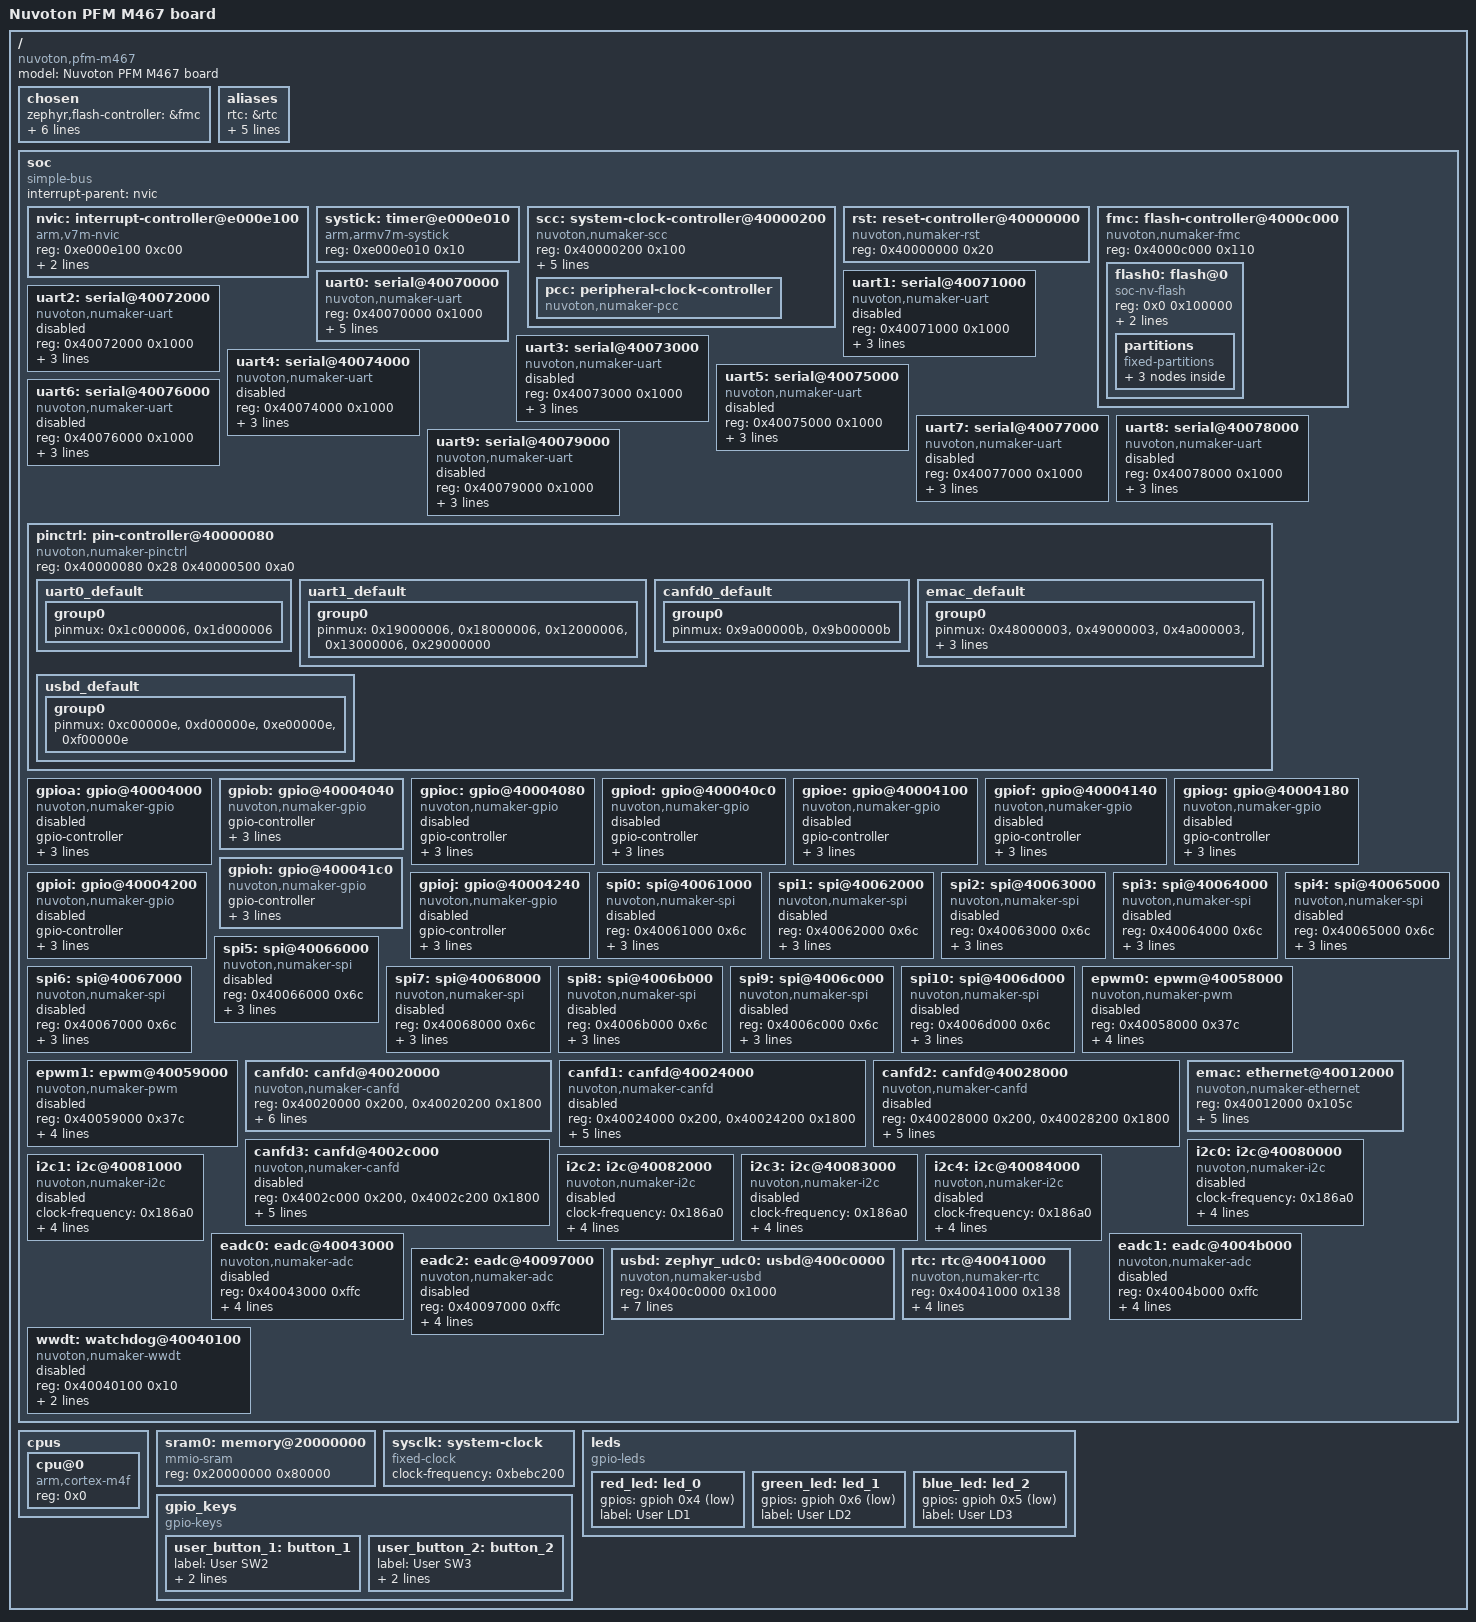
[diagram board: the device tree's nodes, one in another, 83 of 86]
/dts-v1/;

/* node '/' defined in zephyr/dts/common/skeleton.dtsi:9 */
/ {
	#address-cells = < 0x1 >;         /* in zephyr/dts/common/skeleton.dtsi:10 */
	#size-cells = < 0x1 >;            /* in zephyr/dts/common/skeleton.dtsi:11 */
	model = "Nuvoton PFM M467 board"; /* in zephyr/boards/nuvoton/numaker_pfm_m467/numaker_pfm_m467.dts:14 */
	compatible = "nuvoton,pfm-m467",
	             "nuvoton,m467";      /* in zephyr/boards/nuvoton/numaker_pfm_m467/numaker_pfm_m467.dts:15 */

	/* node '/chosen' defined in zephyr/dts/common/skeleton.dtsi:13 */
	chosen {
		zephyr,flash-controller = &fmc;           /* in zephyr/dts/arm/nuvoton/m46x.dtsi:18 */
		zephyr,console = &uart0;                  /* in zephyr/boards/nuvoton/numaker_pfm_m467/numaker_pfm_m467.dts:26 */
		zephyr,shell-uart = &uart0;               /* in zephyr/boards/nuvoton/numaker_pfm_m467/numaker_pfm_m467.dts:27 */
		zephyr,sram = &sram0;                     /* in zephyr/boards/nuvoton/numaker_pfm_m467/numaker_pfm_m467.dts:28 */
		zephyr,flash = &flash0;                   /* in zephyr/boards/nuvoton/numaker_pfm_m467/numaker_pfm_m467.dts:29 */
		zephyr,code-partition = &slot0_partition; /* in zephyr/boards/nuvoton/numaker_pfm_m467/numaker_pfm_m467.dts:30 */
		zephyr,canbus = &canfd0;                  /* in zephyr/boards/nuvoton/numaker_pfm_m467/numaker_pfm_m467.dts:31 */
	};

	/* node '/aliases' defined in zephyr/dts/common/skeleton.dtsi:15 */
	aliases {
		rtc = &rtc;           /* in zephyr/dts/arm/nuvoton/m46x.dtsi:22 */
		led0 = &green_led;    /* in zephyr/boards/nuvoton/numaker_pfm_m467/numaker_pfm_m467.dts:18 */
		led1 = &blue_led;     /* in zephyr/boards/nuvoton/numaker_pfm_m467/numaker_pfm_m467.dts:19 */
		led2 = &red_led;      /* in zephyr/boards/nuvoton/numaker_pfm_m467/numaker_pfm_m467.dts:20 */
		sw0 = &user_button_1; /* in zephyr/boards/nuvoton/numaker_pfm_m467/numaker_pfm_m467.dts:21 */
		sw1 = &user_button_2; /* in zephyr/boards/nuvoton/numaker_pfm_m467/numaker_pfm_m467.dts:22 */
	};

	/* node '/soc' defined in zephyr/dts/arm/armv7-m.dtsi:6 */
	soc {
		#address-cells = < 0x1 >;     /* in zephyr/dts/arm/armv7-m.dtsi:7 */
		#size-cells = < 0x1 >;        /* in zephyr/dts/arm/armv7-m.dtsi:8 */
		compatible = "simple-bus";    /* in zephyr/dts/arm/armv7-m.dtsi:9 */
		interrupt-parent = < &nvic >; /* in zephyr/dts/arm/armv7-m.dtsi:10 */
		ranges;                       /* in zephyr/dts/arm/armv7-m.dtsi:11 */

		/* node '/soc/interrupt-controller@e000e100' defined in zephyr/dts/arm/armv7-m.dtsi:13 */
		nvic: interrupt-controller@e000e100 {
			#address-cells = < 0x1 >;            /* in zephyr/dts/arm/armv7-m.dtsi:14 */
			compatible = "arm,v7m-nvic";         /* in zephyr/dts/arm/armv7-m.dtsi:15 */
			reg = < 0xe000e100 0xc00 >;          /* in zephyr/dts/arm/armv7-m.dtsi:16 */
			interrupt-controller;                /* in zephyr/dts/arm/armv7-m.dtsi:17 */
			#interrupt-cells = < 0x2 >;          /* in zephyr/dts/arm/armv7-m.dtsi:18 */
			arm,num-irq-priority-bits = < 0x4 >; /* in zephyr/dts/arm/nuvoton/m46x.dtsi:638 */
			phandle = < 0x1 >;                   /* in zephyr/dts/arm/armv7-m.dtsi:10 */
		};

		/* node '/soc/timer@e000e010' defined in zephyr/dts/arm/armv7-m.dtsi:21 */
		systick: timer@e000e010 {
			compatible = "arm,armv7m-systick"; /* in zephyr/dts/arm/armv7-m.dtsi:22 */
			reg = < 0xe000e010 0x10 >;         /* in zephyr/dts/arm/armv7-m.dtsi:23 */
		};

		/* node '/soc/system-clock-controller@40000200' defined in zephyr/dts/arm/nuvoton/m46x.dtsi:48 */
		scc: system-clock-controller@40000200 {
			compatible = "nuvoton,numaker-scc"; /* in zephyr/dts/arm/nuvoton/m46x.dtsi:49 */
			reg = < 0x40000200 0x100 >;         /* in zephyr/dts/arm/nuvoton/m46x.dtsi:50 */
			#clock-cells = < 0x0 >;             /* in zephyr/dts/arm/nuvoton/m46x.dtsi:51 */
			lxt = "enable";                     /* in zephyr/dts/arm/nuvoton/m46x.dtsi:53 */
			hirc48m = "enable";                 /* in zephyr/dts/arm/nuvoton/m46x.dtsi:54 */
			clk-pclkdiv = < 0x11 >;             /* in zephyr/dts/arm/nuvoton/m46x.dtsi:55 */
			powerdown-mode = < 0x6 >;           /* in zephyr/dts/arm/nuvoton/m46x.dtsi:58 */
			core-clock = < 0xb71b000 >;         /* in zephyr/boards/nuvoton/numaker_pfm_m467/numaker_pfm_m467.dts:71 */

			/* node '/soc/system-clock-controller@40000200/peripheral-clock-controller' defined in zephyr/dts/arm/nuvoton/m46x.dtsi:60 */
			pcc: peripheral-clock-controller {
				compatible = "nuvoton,numaker-pcc"; /* in zephyr/dts/arm/nuvoton/m46x.dtsi:61 */
				#clock-cells = < 0x3 >;             /* in zephyr/dts/arm/nuvoton/m46x.dtsi:62 */
				phandle = < 0x3 >;                  /* in zephyr/dts/arm/nuvoton/m46x.dtsi:92 */
			};
		};

		/* node '/soc/reset-controller@40000000' defined in zephyr/dts/arm/nuvoton/m46x.dtsi:66 */
		rst: reset-controller@40000000 {
			compatible = "nuvoton,numaker-rst"; /* in zephyr/dts/arm/nuvoton/m46x.dtsi:67 */
			reg = < 0x40000000 0x20 >;          /* in zephyr/dts/arm/nuvoton/m46x.dtsi:68 */
			#reset-cells = < 0x1 >;             /* in zephyr/dts/arm/nuvoton/m46x.dtsi:69 */
			status = "okay";                    /* in zephyr/dts/arm/nuvoton/m46x.dtsi:70 */
			phandle = < 0x2 >;                  /* in zephyr/dts/arm/nuvoton/m46x.dtsi:91 */
		};

		/* node '/soc/flash-controller@4000c000' defined in zephyr/dts/arm/nuvoton/m46x.dtsi:73 */
		fmc: flash-controller@4000c000 {
			compatible = "nuvoton,numaker-fmc"; /* in zephyr/dts/arm/nuvoton/m46x.dtsi:74 */
			reg = < 0x4000c000 0x110 >;         /* in zephyr/dts/arm/nuvoton/m46x.dtsi:75 */
			#address-cells = < 0x1 >;           /* in zephyr/dts/arm/nuvoton/m46x.dtsi:76 */
			#size-cells = < 0x1 >;              /* in zephyr/dts/arm/nuvoton/m46x.dtsi:77 */

			/* node '/soc/flash-controller@4000c000/flash@0' defined in zephyr/dts/arm/nuvoton/m46x.dtsi:79 */
			flash0: flash@0 {
				compatible = "soc-nv-flash";   /* in zephyr/dts/arm/nuvoton/m46x.dtsi:80 */
				reg = < 0x0 0x100000 >;        /* in zephyr/dts/arm/nuvoton/m46x.dtsi:81 */
				erase-block-size = < 0x1000 >; /* in zephyr/dts/arm/nuvoton/m46x.dtsi:82 */
				write-block-size = < 0x4 >;    /* in zephyr/dts/arm/nuvoton/m46x.dtsi:83 */

				/* node '/soc/flash-controller@4000c000/flash@0/partitions' defined in zephyr/boards/nuvoton/numaker_pfm_m467/numaker_pfm_m467.dts:83 */
				partitions {
					compatible = "fixed-partitions"; /* in zephyr/boards/nuvoton/numaker_pfm_m467/numaker_pfm_m467.dts:84 */
					#address-cells = < 0x1 >;        /* in zephyr/boards/nuvoton/numaker_pfm_m467/numaker_pfm_m467.dts:85 */
					#size-cells = < 0x1 >;           /* in zephyr/boards/nuvoton/numaker_pfm_m467/numaker_pfm_m467.dts:86 */

					/* node '/soc/flash-controller@4000c000/flash@0/partitions/partition@0' defined in zephyr/boards/nuvoton/numaker_pfm_m467/numaker_pfm_m467.dts:88 */
					slot0_partition: partition@0 {
						label = "image-0";     /* in zephyr/boards/nuvoton/numaker_pfm_m467/numaker_pfm_m467.dts:89 */
						reg = < 0x0 0x80000 >; /* in zephyr/boards/nuvoton/numaker_pfm_m467/numaker_pfm_m467.dts:90 */
					};

					/* node '/soc/flash-controller@4000c000/flash@0/partitions/partition@80000' defined in zephyr/boards/nuvoton/numaker_pfm_m467/numaker_pfm_m467.dts:93 */
					slot1_partition: partition@80000 {
						label = "image-1";         /* in zephyr/boards/nuvoton/numaker_pfm_m467/numaker_pfm_m467.dts:94 */
						reg = < 0x80000 0x7e000 >; /* in zephyr/boards/nuvoton/numaker_pfm_m467/numaker_pfm_m467.dts:95 */
					};

					/* node '/soc/flash-controller@4000c000/flash@0/partitions/partition@fe000' defined in zephyr/boards/nuvoton/numaker_pfm_m467/numaker_pfm_m467.dts:98 */
					storage_partition: partition@fe000 {
						label = "storage";        /* in zephyr/boards/nuvoton/numaker_pfm_m467/numaker_pfm_m467.dts:99 */
						reg = < 0xfe000 0x2000 >; /* in zephyr/boards/nuvoton/numaker_pfm_m467/numaker_pfm_m467.dts:100 */
					};
				};
			};
		};

		/* node '/soc/serial@40070000' defined in zephyr/dts/arm/nuvoton/m46x.dtsi:87 */
		uart0: serial@40070000 {
			compatible = "nuvoton,numaker-uart";        /* in zephyr/dts/arm/nuvoton/m46x.dtsi:88 */
			reg = < 0x40070000 0x1000 >;                /* in zephyr/dts/arm/nuvoton/m46x.dtsi:89 */
			interrupts = < 0x24 0x0 >;                  /* in zephyr/dts/arm/nuvoton/m46x.dtsi:90 */
			resets = < &rst 0x4000010 >;                /* in zephyr/dts/arm/nuvoton/m46x.dtsi:91 */
			clocks = < &pcc 0x24f03d10 0x3000000 0x0 >; /* in zephyr/dts/arm/nuvoton/m46x.dtsi:92 */
			current-speed = < 0x1c200 >;                /* in zephyr/boards/nuvoton/numaker_pfm_m467/numaker_pfm_m467.dts:110 */
			pinctrl-0 = < &uart0_default >;             /* in zephyr/boards/nuvoton/numaker_pfm_m467/numaker_pfm_m467.dts:111 */
			pinctrl-names = "default";                  /* in zephyr/boards/nuvoton/numaker_pfm_m467/numaker_pfm_m467.dts:112 */
			status = "okay";                            /* in zephyr/boards/nuvoton/numaker_pfm_m467/numaker_pfm_m467.dts:113 */
		};

		/* node '/soc/serial@40071000' defined in zephyr/dts/arm/nuvoton/m46x.dtsi:97 */
		uart1: serial@40071000 {
			compatible = "nuvoton,numaker-uart";        /* in zephyr/dts/arm/nuvoton/m46x.dtsi:98 */
			reg = < 0x40071000 0x1000 >;                /* in zephyr/dts/arm/nuvoton/m46x.dtsi:99 */
			interrupts = < 0x25 0x0 >;                  /* in zephyr/dts/arm/nuvoton/m46x.dtsi:100 */
			resets = < &rst 0x4000011 >;                /* in zephyr/dts/arm/nuvoton/m46x.dtsi:101 */
			clocks = < &pcc 0x24f43d91 0xc000000 0x0 >; /* in zephyr/dts/arm/nuvoton/m46x.dtsi:102 */
			status = "disabled";                        /* in zephyr/dts/arm/nuvoton/m46x.dtsi:104 */
		};

		/* node '/soc/serial@40072000' defined in zephyr/dts/arm/nuvoton/m46x.dtsi:107 */
		uart2: serial@40072000 {
			compatible = "nuvoton,numaker-uart";        /* in zephyr/dts/arm/nuvoton/m46x.dtsi:108 */
			reg = < 0x40072000 0x1000 >;                /* in zephyr/dts/arm/nuvoton/m46x.dtsi:109 */
			interrupts = < 0x30 0x0 >;                  /* in zephyr/dts/arm/nuvoton/m46x.dtsi:110 */
			resets = < &rst 0x4000012 >;                /* in zephyr/dts/arm/nuvoton/m46x.dtsi:111 */
			clocks = < &pcc 0x2cf13c12 0x3000000 0x0 >; /* in zephyr/dts/arm/nuvoton/m46x.dtsi:112 */
			status = "disabled";                        /* in zephyr/dts/arm/nuvoton/m46x.dtsi:114 */
		};

		/* node '/soc/serial@40073000' defined in zephyr/dts/arm/nuvoton/m46x.dtsi:117 */
		uart3: serial@40073000 {
			compatible = "nuvoton,numaker-uart";        /* in zephyr/dts/arm/nuvoton/m46x.dtsi:118 */
			reg = < 0x40073000 0x1000 >;                /* in zephyr/dts/arm/nuvoton/m46x.dtsi:119 */
			interrupts = < 0x31 0x0 >;                  /* in zephyr/dts/arm/nuvoton/m46x.dtsi:120 */
			resets = < &rst 0x4000013 >;                /* in zephyr/dts/arm/nuvoton/m46x.dtsi:121 */
			clocks = < &pcc 0x2cf53c93 0xc000000 0x0 >; /* in zephyr/dts/arm/nuvoton/m46x.dtsi:122 */
			status = "disabled";                        /* in zephyr/dts/arm/nuvoton/m46x.dtsi:124 */
		};

		/* node '/soc/serial@40074000' defined in zephyr/dts/arm/nuvoton/m46x.dtsi:127 */
		uart4: serial@40074000 {
			compatible = "nuvoton,numaker-uart";         /* in zephyr/dts/arm/nuvoton/m46x.dtsi:128 */
			reg = < 0x40074000 0x1000 >;                 /* in zephyr/dts/arm/nuvoton/m46x.dtsi:129 */
			interrupts = < 0x4a 0x0 >;                   /* in zephyr/dts/arm/nuvoton/m46x.dtsi:130 */
			resets = < &rst 0x4000014 >;                 /* in zephyr/dts/arm/nuvoton/m46x.dtsi:131 */
			clocks = < &pcc 0x2cf93d14 0x30000000 0x0 >; /* in zephyr/dts/arm/nuvoton/m46x.dtsi:132 */
			status = "disabled";                         /* in zephyr/dts/arm/nuvoton/m46x.dtsi:134 */
		};

		/* node '/soc/serial@40075000' defined in zephyr/dts/arm/nuvoton/m46x.dtsi:137 */
		uart5: serial@40075000 {
			compatible = "nuvoton,numaker-uart";         /* in zephyr/dts/arm/nuvoton/m46x.dtsi:138 */
			reg = < 0x40075000 0x1000 >;                 /* in zephyr/dts/arm/nuvoton/m46x.dtsi:139 */
			interrupts = < 0x4b 0x0 >;                   /* in zephyr/dts/arm/nuvoton/m46x.dtsi:140 */
			resets = < &rst 0x4000015 >;                 /* in zephyr/dts/arm/nuvoton/m46x.dtsi:141 */
			clocks = < &pcc 0x2cfd3d95 0xc0000000 0x0 >; /* in zephyr/dts/arm/nuvoton/m46x.dtsi:142 */
			status = "disabled";                         /* in zephyr/dts/arm/nuvoton/m46x.dtsi:144 */
		};

		/* node '/soc/serial@40076000' defined in zephyr/dts/arm/nuvoton/m46x.dtsi:147 */
		uart6: serial@40076000 {
			compatible = "nuvoton,numaker-uart";       /* in zephyr/dts/arm/nuvoton/m46x.dtsi:148 */
			reg = < 0x40076000 0x1000 >;               /* in zephyr/dts/arm/nuvoton/m46x.dtsi:149 */
			interrupts = < 0x66 0x0 >;                 /* in zephyr/dts/arm/nuvoton/m46x.dtsi:150 */
			resets = < &rst 0x4000016 >;               /* in zephyr/dts/arm/nuvoton/m46x.dtsi:151 */
			clocks = < &pcc 0x2ce93e16 0x300000 0x0 >; /* in zephyr/dts/arm/nuvoton/m46x.dtsi:152 */
			status = "disabled";                       /* in zephyr/dts/arm/nuvoton/m46x.dtsi:154 */
		};

		/* node '/soc/serial@40077000' defined in zephyr/dts/arm/nuvoton/m46x.dtsi:157 */
		uart7: serial@40077000 {
			compatible = "nuvoton,numaker-uart";       /* in zephyr/dts/arm/nuvoton/m46x.dtsi:158 */
			reg = < 0x40077000 0x1000 >;               /* in zephyr/dts/arm/nuvoton/m46x.dtsi:159 */
			interrupts = < 0x67 0x0 >;                 /* in zephyr/dts/arm/nuvoton/m46x.dtsi:160 */
			resets = < &rst 0x4000017 >;               /* in zephyr/dts/arm/nuvoton/m46x.dtsi:161 */
			clocks = < &pcc 0x2ced3e97 0xc00000 0x0 >; /* in zephyr/dts/arm/nuvoton/m46x.dtsi:162 */
			status = "disabled";                       /* in zephyr/dts/arm/nuvoton/m46x.dtsi:164 */
		};

		/* node '/soc/serial@40078000' defined in zephyr/dts/arm/nuvoton/m46x.dtsi:167 */
		uart8: serial@40078000 {
			compatible = "nuvoton,numaker-uart";       /* in zephyr/dts/arm/nuvoton/m46x.dtsi:168 */
			reg = < 0x40078000 0x1000 >;               /* in zephyr/dts/arm/nuvoton/m46x.dtsi:169 */
			interrupts = < 0x63 0x0 >;                 /* in zephyr/dts/arm/nuvoton/m46x.dtsi:170 */
			resets = < &rst 0x18000010 >;              /* in zephyr/dts/arm/nuvoton/m46x.dtsi:171 */
			clocks = < &pcc 0x68e97e10 0x300000 0x0 >; /* in zephyr/dts/arm/nuvoton/m46x.dtsi:172 */
			status = "disabled";                       /* in zephyr/dts/arm/nuvoton/m46x.dtsi:174 */
		};

		/* node '/soc/serial@40079000' defined in zephyr/dts/arm/nuvoton/m46x.dtsi:177 */
		uart9: serial@40079000 {
			compatible = "nuvoton,numaker-uart";       /* in zephyr/dts/arm/nuvoton/m46x.dtsi:178 */
			reg = < 0x40079000 0x1000 >;               /* in zephyr/dts/arm/nuvoton/m46x.dtsi:179 */
			interrupts = < 0x64 0x0 >;                 /* in zephyr/dts/arm/nuvoton/m46x.dtsi:180 */
			resets = < &rst 0x18000011 >;              /* in zephyr/dts/arm/nuvoton/m46x.dtsi:181 */
			clocks = < &pcc 0x68ed7e91 0xc00000 0x0 >; /* in zephyr/dts/arm/nuvoton/m46x.dtsi:182 */
			status = "disabled";                       /* in zephyr/dts/arm/nuvoton/m46x.dtsi:184 */
		};

		/* node '/soc/pin-controller@40000080' defined in zephyr/dts/arm/nuvoton/m46x.dtsi:187 */
		pinctrl: pin-controller@40000080 {
			compatible = "nuvoton,numaker-pinctrl";    /* in zephyr/dts/arm/nuvoton/m46x.dtsi:188 */
			reg = < 0x40000080 0x28 0x40000500 0xa0 >; /* in zephyr/dts/arm/nuvoton/m46x.dtsi:189 */
			reg-names = "mfos",
			            "mfp";                         /* in zephyr/dts/arm/nuvoton/m46x.dtsi:191 */
			status = "okay";                           /* in zephyr/dts/arm/nuvoton/m46x.dtsi:192 */

			/* node '/soc/pin-controller@40000080/uart0_default' defined in zephyr/boards/nuvoton/numaker_pfm_m467/numaker_pfm_m467-pinctrl.dtsi:10 */
			uart0_default: uart0_default {
				phandle = < 0x4 >; /* in zephyr/boards/nuvoton/numaker_pfm_m467/numaker_pfm_m467.dts:111 */

				/* node '/soc/pin-controller@40000080/uart0_default/group0' defined in zephyr/boards/nuvoton/numaker_pfm_m467/numaker_pfm_m467-pinctrl.dtsi:11 */
				group0 {
					pinmux = < 0x1c000006 >,
					         < 0x1d000006 >; /* in zephyr/boards/nuvoton/numaker_pfm_m467/numaker_pfm_m467-pinctrl.dtsi:12 */
				};
			};

			/* node '/soc/pin-controller@40000080/uart1_default' defined in zephyr/boards/nuvoton/numaker_pfm_m467/numaker_pfm_m467-pinctrl.dtsi:18 */
			uart1_default: uart1_default {

				/* node '/soc/pin-controller@40000080/uart1_default/group0' defined in zephyr/boards/nuvoton/numaker_pfm_m467/numaker_pfm_m467-pinctrl.dtsi:19 */
				group0 {
					pinmux = < 0x19000006 >,
					         < 0x18000006 >,
					         < 0x12000006 >,
					         < 0x13000006 >,
					         < 0x29000000 >; /* in zephyr/boards/nuvoton/numaker_pfm_m467/numaker_pfm_m467-pinctrl.dtsi:20 */
				};
			};

			/* node '/soc/pin-controller@40000080/canfd0_default' defined in zephyr/boards/nuvoton/numaker_pfm_m467/numaker_pfm_m467-pinctrl.dtsi:29 */
			canfd0_default: canfd0_default {
				phandle = < 0x5 >; /* in zephyr/boards/nuvoton/numaker_pfm_m467/numaker_pfm_m467.dts:117 */

				/* node '/soc/pin-controller@40000080/canfd0_default/group0' defined in zephyr/boards/nuvoton/numaker_pfm_m467/numaker_pfm_m467-pinctrl.dtsi:30 */
				group0 {
					pinmux = < 0x9a00000b >,
					         < 0x9b00000b >; /* in zephyr/boards/nuvoton/numaker_pfm_m467/numaker_pfm_m467-pinctrl.dtsi:31 */
				};
			};

			/* node '/soc/pin-controller@40000080/emac_default' defined in zephyr/boards/nuvoton/numaker_pfm_m467/numaker_pfm_m467-pinctrl.dtsi:37 */
			emac_default: emac_default {
				phandle = < 0x6 >; /* in zephyr/boards/nuvoton/numaker_pfm_m467/numaker_pfm_m467.dts:123 */

				/* node '/soc/pin-controller@40000080/emac_default/group0' defined in zephyr/boards/nuvoton/numaker_pfm_m467/numaker_pfm_m467-pinctrl.dtsi:38 */
				group0 {
					pinmux = < 0x48000003 >,
					         < 0x49000003 >,
					         < 0x4a000003 >,
					         < 0x4b000003 >,
					         < 0x4c000003 >,
					         < 0x28000003 >,
					         < 0x27000003 >,
					         < 0x26000003 >,
					         < 0x7000003 >,
					         < 0x6000003 >,
					         < 0x16000003 >; /* in zephyr/boards/nuvoton/numaker_pfm_m467/numaker_pfm_m467-pinctrl.dtsi:39 */
				};
			};

			/* node '/soc/pin-controller@40000080/usbd_default' defined in zephyr/boards/nuvoton/numaker_pfm_m467/numaker_pfm_m467-pinctrl.dtsi:54 */
			usbd_default: usbd_default {
				phandle = < 0x7 >; /* in zephyr/boards/nuvoton/numaker_pfm_m467/numaker_pfm_m467.dts:130 */

				/* node '/soc/pin-controller@40000080/usbd_default/group0' defined in zephyr/boards/nuvoton/numaker_pfm_m467/numaker_pfm_m467-pinctrl.dtsi:55 */
				group0 {
					pinmux = < 0xc00000e >,
					         < 0xd00000e >,
					         < 0xe00000e >,
					         < 0xf00000e >; /* in zephyr/boards/nuvoton/numaker_pfm_m467/numaker_pfm_m467-pinctrl.dtsi:56 */
				};
			};
		};

		/* node '/soc/gpio@40004000' defined in zephyr/dts/arm/nuvoton/m46x.dtsi:195 */
		gpioa: gpio@40004000 {
			compatible = "nuvoton,numaker-gpio"; /* in zephyr/dts/arm/nuvoton/m46x.dtsi:196 */
			gpio-controller;                     /* in zephyr/dts/arm/nuvoton/m46x.dtsi:197 */
			#gpio-cells = < 0x2 >;               /* in zephyr/dts/arm/nuvoton/m46x.dtsi:198 */
			reg = < 0x40004000 0x40 >;           /* in zephyr/dts/arm/nuvoton/m46x.dtsi:199 */
			clocks = < &pcc 0x18 0x0 0x0 >;      /* in zephyr/dts/arm/nuvoton/m46x.dtsi:200 */
			status = "disabled";                 /* in zephyr/dts/arm/nuvoton/m46x.dtsi:201 */
			interrupts = < 0x10 0x2 >;           /* in zephyr/dts/arm/nuvoton/m46x.dtsi:202 */
		};

		/* node '/soc/gpio@40004040' defined in zephyr/dts/arm/nuvoton/m46x.dtsi:205 */
		gpiob: gpio@40004040 {
			compatible = "nuvoton,numaker-gpio"; /* in zephyr/dts/arm/nuvoton/m46x.dtsi:206 */
			gpio-controller;                     /* in zephyr/dts/arm/nuvoton/m46x.dtsi:207 */
			#gpio-cells = < 0x2 >;               /* in zephyr/dts/arm/nuvoton/m46x.dtsi:208 */
			reg = < 0x40004040 0x40 >;           /* in zephyr/dts/arm/nuvoton/m46x.dtsi:209 */
			clocks = < &pcc 0x19 0x0 0x0 >;      /* in zephyr/dts/arm/nuvoton/m46x.dtsi:210 */
			interrupts = < 0x11 0x2 >;           /* in zephyr/dts/arm/nuvoton/m46x.dtsi:212 */
			status = "okay";                     /* in zephyr/boards/nuvoton/numaker_pfm_m467/numaker_pfm_m467.dts:75 */
		};

		/* node '/soc/gpio@40004080' defined in zephyr/dts/arm/nuvoton/m46x.dtsi:215 */
		gpioc: gpio@40004080 {
			compatible = "nuvoton,numaker-gpio"; /* in zephyr/dts/arm/nuvoton/m46x.dtsi:216 */
			gpio-controller;                     /* in zephyr/dts/arm/nuvoton/m46x.dtsi:217 */
			#gpio-cells = < 0x2 >;               /* in zephyr/dts/arm/nuvoton/m46x.dtsi:218 */
			reg = < 0x40004080 0x40 >;           /* in zephyr/dts/arm/nuvoton/m46x.dtsi:219 */
			clocks = < &pcc 0x1a 0x0 0x0 >;      /* in zephyr/dts/arm/nuvoton/m46x.dtsi:220 */
			status = "disabled";                 /* in zephyr/dts/arm/nuvoton/m46x.dtsi:221 */
			interrupts = < 0x12 0x2 >;           /* in zephyr/dts/arm/nuvoton/m46x.dtsi:222 */
		};

		/* node '/soc/gpio@400040c0' defined in zephyr/dts/arm/nuvoton/m46x.dtsi:225 */
		gpiod: gpio@400040c0 {
			compatible = "nuvoton,numaker-gpio"; /* in zephyr/dts/arm/nuvoton/m46x.dtsi:226 */
			gpio-controller;                     /* in zephyr/dts/arm/nuvoton/m46x.dtsi:227 */
			#gpio-cells = < 0x2 >;               /* in zephyr/dts/arm/nuvoton/m46x.dtsi:228 */
			reg = < 0x400040c0 0x40 >;           /* in zephyr/dts/arm/nuvoton/m46x.dtsi:229 */
			clocks = < &pcc 0x1b 0x0 0x0 >;      /* in zephyr/dts/arm/nuvoton/m46x.dtsi:230 */
			status = "disabled";                 /* in zephyr/dts/arm/nuvoton/m46x.dtsi:231 */
			interrupts = < 0x13 0x2 >;           /* in zephyr/dts/arm/nuvoton/m46x.dtsi:232 */
		};

		/* node '/soc/gpio@40004100' defined in zephyr/dts/arm/nuvoton/m46x.dtsi:235 */
		gpioe: gpio@40004100 {
			compatible = "nuvoton,numaker-gpio"; /* in zephyr/dts/arm/nuvoton/m46x.dtsi:236 */
			gpio-controller;                     /* in zephyr/dts/arm/nuvoton/m46x.dtsi:237 */
			#gpio-cells = < 0x2 >;               /* in zephyr/dts/arm/nuvoton/m46x.dtsi:238 */
			reg = < 0x40004100 0x40 >;           /* in zephyr/dts/arm/nuvoton/m46x.dtsi:239 */
			clocks = < &pcc 0x1c 0x0 0x0 >;      /* in zephyr/dts/arm/nuvoton/m46x.dtsi:240 */
			status = "disabled";                 /* in zephyr/dts/arm/nuvoton/m46x.dtsi:241 */
			interrupts = < 0x14 0x2 >;           /* in zephyr/dts/arm/nuvoton/m46x.dtsi:242 */
		};

		/* node '/soc/gpio@40004140' defined in zephyr/dts/arm/nuvoton/m46x.dtsi:245 */
		gpiof: gpio@40004140 {
			compatible = "nuvoton,numaker-gpio"; /* in zephyr/dts/arm/nuvoton/m46x.dtsi:246 */
			gpio-controller;                     /* in zephyr/dts/arm/nuvoton/m46x.dtsi:247 */
			#gpio-cells = < 0x2 >;               /* in zephyr/dts/arm/nuvoton/m46x.dtsi:248 */
			reg = < 0x40004140 0x40 >;           /* in zephyr/dts/arm/nuvoton/m46x.dtsi:249 */
			clocks = < &pcc 0x1d 0x0 0x0 >;      /* in zephyr/dts/arm/nuvoton/m46x.dtsi:250 */
			status = "disabled";                 /* in zephyr/dts/arm/nuvoton/m46x.dtsi:251 */
			interrupts = < 0x15 0x2 >;           /* in zephyr/dts/arm/nuvoton/m46x.dtsi:252 */
		};

		/* node '/soc/gpio@40004180' defined in zephyr/dts/arm/nuvoton/m46x.dtsi:255 */
		gpiog: gpio@40004180 {
			compatible = "nuvoton,numaker-gpio"; /* in zephyr/dts/arm/nuvoton/m46x.dtsi:256 */
			gpio-controller;                     /* in zephyr/dts/arm/nuvoton/m46x.dtsi:257 */
			#gpio-cells = < 0x2 >;               /* in zephyr/dts/arm/nuvoton/m46x.dtsi:258 */
			reg = < 0x40004180 0x40 >;           /* in zephyr/dts/arm/nuvoton/m46x.dtsi:259 */
			clocks = < &pcc 0x1e 0x0 0x0 >;      /* in zephyr/dts/arm/nuvoton/m46x.dtsi:260 */
			status = "disabled";                 /* in zephyr/dts/arm/nuvoton/m46x.dtsi:261 */
			interrupts = < 0x48 0x2 >;           /* in zephyr/dts/arm/nuvoton/m46x.dtsi:262 */
		};

		/* node '/soc/gpio@400041c0' defined in zephyr/dts/arm/nuvoton/m46x.dtsi:265 */
		gpioh: gpio@400041c0 {
			compatible = "nuvoton,numaker-gpio"; /* in zephyr/dts/arm/nuvoton/m46x.dtsi:266 */
			gpio-controller;                     /* in zephyr/dts/arm/nuvoton/m46x.dtsi:267 */
			#gpio-cells = < 0x2 >;               /* in zephyr/dts/arm/nuvoton/m46x.dtsi:268 */
			reg = < 0x400041c0 0x40 >;           /* in zephyr/dts/arm/nuvoton/m46x.dtsi:269 */
			clocks = < &pcc 0x1f 0x0 0x0 >;      /* in zephyr/dts/arm/nuvoton/m46x.dtsi:270 */
			interrupts = < 0x58 0x2 >;           /* in zephyr/dts/arm/nuvoton/m46x.dtsi:272 */
			status = "okay";                     /* in zephyr/boards/nuvoton/numaker_pfm_m467/numaker_pfm_m467.dts:79 */
			phandle = < 0x8 >;                   /* in zephyr/boards/nuvoton/numaker_pfm_m467/numaker_pfm_m467.dts:38 */
		};

		/* node '/soc/gpio@40004200' defined in zephyr/dts/arm/nuvoton/m46x.dtsi:275 */
		gpioi: gpio@40004200 {
			compatible = "nuvoton,numaker-gpio";  /* in zephyr/dts/arm/nuvoton/m46x.dtsi:276 */
			gpio-controller;                      /* in zephyr/dts/arm/nuvoton/m46x.dtsi:277 */
			#gpio-cells = < 0x2 >;                /* in zephyr/dts/arm/nuvoton/m46x.dtsi:278 */
			reg = < 0x40004200 0x40 >;            /* in zephyr/dts/arm/nuvoton/m46x.dtsi:279 */
			clocks = < &pcc 0x80000018 0x0 0x0 >; /* in zephyr/dts/arm/nuvoton/m46x.dtsi:280 */
			status = "disabled";                  /* in zephyr/dts/arm/nuvoton/m46x.dtsi:281 */
			interrupts = < 0x6e 0x2 >;            /* in zephyr/dts/arm/nuvoton/m46x.dtsi:282 */
		};

		/* node '/soc/gpio@40004240' defined in zephyr/dts/arm/nuvoton/m46x.dtsi:285 */
		gpioj: gpio@40004240 {
			compatible = "nuvoton,numaker-gpio";  /* in zephyr/dts/arm/nuvoton/m46x.dtsi:286 */
			gpio-controller;                      /* in zephyr/dts/arm/nuvoton/m46x.dtsi:287 */
			#gpio-cells = < 0x2 >;                /* in zephyr/dts/arm/nuvoton/m46x.dtsi:288 */
			reg = < 0x40004240 0x40 >;            /* in zephyr/dts/arm/nuvoton/m46x.dtsi:289 */
			clocks = < &pcc 0x80000019 0x0 0x0 >; /* in zephyr/dts/arm/nuvoton/m46x.dtsi:290 */
			status = "disabled";                  /* in zephyr/dts/arm/nuvoton/m46x.dtsi:291 */
			interrupts = < 0x3d 0x2 >;            /* in zephyr/dts/arm/nuvoton/m46x.dtsi:292 */
		};

		/* node '/soc/spi@40061000' defined in zephyr/dts/arm/nuvoton/m46x.dtsi:295 */
		spi0: spi@40061000 {
			compatible = "nuvoton,numaker-spi";    /* in zephyr/dts/arm/nuvoton/m46x.dtsi:296 */
			reg = < 0x40061000 0x6c >;             /* in zephyr/dts/arm/nuvoton/m46x.dtsi:297 */
			interrupts = < 0x17 0x0 >;             /* in zephyr/dts/arm/nuvoton/m46x.dtsi:298 */
			resets = < &rst 0x400000d >;           /* in zephyr/dts/arm/nuvoton/m46x.dtsi:299 */
			clocks = < &pcc 0x29c8000d 0x30 0x0 >; /* in zephyr/dts/arm/nuvoton/m46x.dtsi:300 */
			#address-cells = < 0x1 >;              /* in zephyr/dts/arm/nuvoton/m46x.dtsi:301 */
			#size-cells = < 0x0 >;                 /* in zephyr/dts/arm/nuvoton/m46x.dtsi:302 */
			status = "disabled";                   /* in zephyr/dts/arm/nuvoton/m46x.dtsi:303 */
		};

		/* node '/soc/spi@40062000' defined in zephyr/dts/arm/nuvoton/m46x.dtsi:306 */
		spi1: spi@40062000 {
			compatible = "nuvoton,numaker-spi";      /* in zephyr/dts/arm/nuvoton/m46x.dtsi:307 */
			reg = < 0x40062000 0x6c >;               /* in zephyr/dts/arm/nuvoton/m46x.dtsi:308 */
			interrupts = < 0x33 0x0 >;               /* in zephyr/dts/arm/nuvoton/m46x.dtsi:309 */
			resets = < &rst 0x400000e >;             /* in zephyr/dts/arm/nuvoton/m46x.dtsi:310 */
			clocks = < &pcc 0x29d8000e 0x3000 0x0 >; /* in zephyr/dts/arm/nuvoton/m46x.dtsi:311 */
			#address-cells = < 0x1 >;                /* in zephyr/dts/arm/nuvoton/m46x.dtsi:312 */
			#size-cells = < 0x0 >;                   /* in zephyr/dts/arm/nuvoton/m46x.dtsi:313 */
			status = "disabled";                     /* in zephyr/dts/arm/nuvoton/m46x.dtsi:314 */
		};

		/* node '/soc/spi@40063000' defined in zephyr/dts/arm/nuvoton/m46x.dtsi:317 */
		spi2: spi@40063000 {
			compatible = "nuvoton,numaker-spi";     /* in zephyr/dts/arm/nuvoton/m46x.dtsi:318 */
			reg = < 0x40063000 0x6c >;              /* in zephyr/dts/arm/nuvoton/m46x.dtsi:319 */
			interrupts = < 0x34 0x0 >;              /* in zephyr/dts/arm/nuvoton/m46x.dtsi:320 */
			resets = < &rst 0x400000f >;            /* in zephyr/dts/arm/nuvoton/m46x.dtsi:321 */
			clocks = < &pcc 0x2dd2000f 0x600 0x0 >; /* in zephyr/dts/arm/nuvoton/m46x.dtsi:322 */
			#address-cells = < 0x1 >;               /* in zephyr/dts/arm/nuvoton/m46x.dtsi:323 */
			#size-cells = < 0x0 >;                  /* in zephyr/dts/arm/nuvoton/m46x.dtsi:324 */
			status = "disabled";                    /* in zephyr/dts/arm/nuvoton/m46x.dtsi:325 */
		};

		/* node '/soc/spi@40064000' defined in zephyr/dts/arm/nuvoton/m46x.dtsi:328 */
		spi3: spi@40064000 {
			compatible = "nuvoton,numaker-spi";      /* in zephyr/dts/arm/nuvoton/m46x.dtsi:329 */
			reg = < 0x40064000 0x6c >;               /* in zephyr/dts/arm/nuvoton/m46x.dtsi:330 */
			interrupts = < 0x3e 0x0 >;               /* in zephyr/dts/arm/nuvoton/m46x.dtsi:331 */
			resets = < &rst 0x8000006 >;             /* in zephyr/dts/arm/nuvoton/m46x.dtsi:332 */
			clocks = < &pcc 0x4dd80006 0x3000 0x0 >; /* in zephyr/dts/arm/nuvoton/m46x.dtsi:333 */
			#address-cells = < 0x1 >;                /* in zephyr/dts/arm/nuvoton/m46x.dtsi:334 */
			#size-cells = < 0x0 >;                   /* in zephyr/dts/arm/nuvoton/m46x.dtsi:335 */
			status = "disabled";                     /* in zephyr/dts/arm/nuvoton/m46x.dtsi:336 */
		};

		/* node '/soc/spi@40065000' defined in zephyr/dts/arm/nuvoton/m46x.dtsi:339 */
		spi4: spi@40065000 {
			compatible = "nuvoton,numaker-spi";   /* in zephyr/dts/arm/nuvoton/m46x.dtsi:340 */
			reg = < 0x40065000 0x6c >;            /* in zephyr/dts/arm/nuvoton/m46x.dtsi:341 */
			interrupts = < 0x3f 0x0 >;            /* in zephyr/dts/arm/nuvoton/m46x.dtsi:342 */
			resets = < &rst 0x8000007 >;          /* in zephyr/dts/arm/nuvoton/m46x.dtsi:343 */
			clocks = < &pcc 0x51c00007 0x3 0x0 >; /* in zephyr/dts/arm/nuvoton/m46x.dtsi:344 */
			#address-cells = < 0x1 >;             /* in zephyr/dts/arm/nuvoton/m46x.dtsi:345 */
			#size-cells = < 0x0 >;                /* in zephyr/dts/arm/nuvoton/m46x.dtsi:346 */
			status = "disabled";                  /* in zephyr/dts/arm/nuvoton/m46x.dtsi:347 */
		};

		/* node '/soc/spi@40066000' defined in zephyr/dts/arm/nuvoton/m46x.dtsi:350 */
		spi5: spi@40066000 {
			compatible = "nuvoton,numaker-spi";    /* in zephyr/dts/arm/nuvoton/m46x.dtsi:351 */
			reg = < 0x40066000 0x6c >;             /* in zephyr/dts/arm/nuvoton/m46x.dtsi:352 */
			interrupts = < 0x39 0x0 >;             /* in zephyr/dts/arm/nuvoton/m46x.dtsi:353 */
			resets = < &rst 0x18000008 >;          /* in zephyr/dts/arm/nuvoton/m46x.dtsi:354 */
			clocks = < &pcc 0x71c80008 0x30 0x0 >; /* in zephyr/dts/arm/nuvoton/m46x.dtsi:355 */
			#address-cells = < 0x1 >;              /* in zephyr/dts/arm/nuvoton/m46x.dtsi:356 */
			#size-cells = < 0x0 >;                 /* in zephyr/dts/arm/nuvoton/m46x.dtsi:357 */
			status = "disabled";                   /* in zephyr/dts/arm/nuvoton/m46x.dtsi:358 */
		};

		/* node '/soc/spi@40067000' defined in zephyr/dts/arm/nuvoton/m46x.dtsi:361 */
		spi6: spi@40067000 {
			compatible = "nuvoton,numaker-spi";     /* in zephyr/dts/arm/nuvoton/m46x.dtsi:362 */
			reg = < 0x40067000 0x6c >;              /* in zephyr/dts/arm/nuvoton/m46x.dtsi:363 */
			interrupts = < 0x46 0x0 >;              /* in zephyr/dts/arm/nuvoton/m46x.dtsi:364 */
			resets = < &rst 0x18000009 >;           /* in zephyr/dts/arm/nuvoton/m46x.dtsi:365 */
			clocks = < &pcc 0x71d00009 0x300 0x0 >; /* in zephyr/dts/arm/nuvoton/m46x.dtsi:366 */
			#address-cells = < 0x1 >;               /* in zephyr/dts/arm/nuvoton/m46x.dtsi:367 */
			#size-cells = < 0x0 >;                  /* in zephyr/dts/arm/nuvoton/m46x.dtsi:368 */
			status = "disabled";                    /* in zephyr/dts/arm/nuvoton/m46x.dtsi:369 */
		};

		/* node '/soc/spi@40068000' defined in zephyr/dts/arm/nuvoton/m46x.dtsi:372 */
		spi7: spi@40068000 {
			compatible = "nuvoton,numaker-spi";      /* in zephyr/dts/arm/nuvoton/m46x.dtsi:373 */
			reg = < 0x40068000 0x6c >;               /* in zephyr/dts/arm/nuvoton/m46x.dtsi:374 */
			interrupts = < 0x4d 0x0 >;               /* in zephyr/dts/arm/nuvoton/m46x.dtsi:375 */
			resets = < &rst 0x1800000a >;            /* in zephyr/dts/arm/nuvoton/m46x.dtsi:376 */
			clocks = < &pcc 0x71d8000a 0x3000 0x0 >; /* in zephyr/dts/arm/nuvoton/m46x.dtsi:377 */
			#address-cells = < 0x1 >;                /* in zephyr/dts/arm/nuvoton/m46x.dtsi:378 */
			#size-cells = < 0x0 >;                   /* in zephyr/dts/arm/nuvoton/m46x.dtsi:379 */
			status = "disabled";                     /* in zephyr/dts/arm/nuvoton/m46x.dtsi:380 */
		};

		/* node '/soc/spi@4006b000' defined in zephyr/dts/arm/nuvoton/m46x.dtsi:383 */
		spi8: spi@4006b000 {
			compatible = "nuvoton,numaker-spi";       /* in zephyr/dts/arm/nuvoton/m46x.dtsi:384 */
			reg = < 0x4006b000 0x6c >;                /* in zephyr/dts/arm/nuvoton/m46x.dtsi:385 */
			interrupts = < 0x6c 0x0 >;                /* in zephyr/dts/arm/nuvoton/m46x.dtsi:386 */
			resets = < &rst 0x1800000b >;             /* in zephyr/dts/arm/nuvoton/m46x.dtsi:387 */
			clocks = < &pcc 0x71e0000b 0x30000 0x0 >; /* in zephyr/dts/arm/nuvoton/m46x.dtsi:388 */
			#address-cells = < 0x1 >;                 /* in zephyr/dts/arm/nuvoton/m46x.dtsi:389 */
			#size-cells = < 0x0 >;                    /* in zephyr/dts/arm/nuvoton/m46x.dtsi:390 */
			status = "disabled";                      /* in zephyr/dts/arm/nuvoton/m46x.dtsi:391 */
		};

		/* node '/soc/spi@4006c000' defined in zephyr/dts/arm/nuvoton/m46x.dtsi:394 */
		spi9: spi@4006c000 {
			compatible = "nuvoton,numaker-spi";        /* in zephyr/dts/arm/nuvoton/m46x.dtsi:395 */
			reg = < 0x4006c000 0x6c >;                 /* in zephyr/dts/arm/nuvoton/m46x.dtsi:396 */
			interrupts = < 0x6f 0x0 >;                 /* in zephyr/dts/arm/nuvoton/m46x.dtsi:397 */
			resets = < &rst 0x1800000c >;              /* in zephyr/dts/arm/nuvoton/m46x.dtsi:398 */
			clocks = < &pcc 0x71e8000c 0x300000 0x0 >; /* in zephyr/dts/arm/nuvoton/m46x.dtsi:399 */
			#address-cells = < 0x1 >;                  /* in zephyr/dts/arm/nuvoton/m46x.dtsi:400 */
			#size-cells = < 0x0 >;                     /* in zephyr/dts/arm/nuvoton/m46x.dtsi:401 */
			status = "disabled";                       /* in zephyr/dts/arm/nuvoton/m46x.dtsi:402 */
		};

		/* node '/soc/spi@4006d000' defined in zephyr/dts/arm/nuvoton/m46x.dtsi:405 */
		spi10: spi@4006d000 {
			compatible = "nuvoton,numaker-spi";         /* in zephyr/dts/arm/nuvoton/m46x.dtsi:406 */
			reg = < 0x4006d000 0x6c >;                  /* in zephyr/dts/arm/nuvoton/m46x.dtsi:407 */
			interrupts = < 0x77 0x0 >;                  /* in zephyr/dts/arm/nuvoton/m46x.dtsi:408 */
			resets = < &rst 0x1800000d >;               /* in zephyr/dts/arm/nuvoton/m46x.dtsi:409 */
			clocks = < &pcc 0x71f0000d 0x3000000 0x0 >; /* in zephyr/dts/arm/nuvoton/m46x.dtsi:410 */
			#address-cells = < 0x1 >;                   /* in zephyr/dts/arm/nuvoton/m46x.dtsi:411 */
			#size-cells = < 0x0 >;                      /* in zephyr/dts/arm/nuvoton/m46x.dtsi:412 */
			status = "disabled";                        /* in zephyr/dts/arm/nuvoton/m46x.dtsi:413 */
		};

		/* node '/soc/epwm@40058000' defined in zephyr/dts/arm/nuvoton/m46x.dtsi:416 */
		epwm0: epwm@40058000 {
			compatible = "nuvoton,numaker-pwm";   /* in zephyr/dts/arm/nuvoton/m46x.dtsi:417 */
			reg = < 0x40058000 0x37c >;           /* in zephyr/dts/arm/nuvoton/m46x.dtsi:418 */
			interrupts = < 0x19 0x0 >,
			             < 0x1a 0x0 >,
			             < 0x1b 0x0 >;            /* in zephyr/dts/arm/nuvoton/m46x.dtsi:419 */
			interrupt-names = "pair0",
			                  "pair1",
			                  "pair2";            /* in zephyr/dts/arm/nuvoton/m46x.dtsi:420 */
			resets = < &rst 0x8000010 >;          /* in zephyr/dts/arm/nuvoton/m46x.dtsi:421 */
			prescaler = < 0x13 >;                 /* in zephyr/dts/arm/nuvoton/m46x.dtsi:422 */
			clocks = < &pcc 0x48400010 0x1 0x0 >; /* in zephyr/dts/arm/nuvoton/m46x.dtsi:423 */
			#pwm-cells = < 0x3 >;                 /* in zephyr/dts/arm/nuvoton/m46x.dtsi:424 */
			status = "disabled";                  /* in zephyr/dts/arm/nuvoton/m46x.dtsi:425 */
		};

		/* node '/soc/epwm@40059000' defined in zephyr/dts/arm/nuvoton/m46x.dtsi:428 */
		epwm1: epwm@40059000 {
			compatible = "nuvoton,numaker-pwm";   /* in zephyr/dts/arm/nuvoton/m46x.dtsi:429 */
			reg = < 0x40059000 0x37c >;           /* in zephyr/dts/arm/nuvoton/m46x.dtsi:430 */
			interrupts = < 0x1d 0x0 >,
			             < 0x1e 0x0 >,
			             < 0x1f 0x0 >;            /* in zephyr/dts/arm/nuvoton/m46x.dtsi:431 */
			interrupt-names = "pair0",
			                  "pair1",
			                  "pair2";            /* in zephyr/dts/arm/nuvoton/m46x.dtsi:432 */
			resets = < &rst 0x8000011 >;          /* in zephyr/dts/arm/nuvoton/m46x.dtsi:433 */
			prescaler = < 0x13 >;                 /* in zephyr/dts/arm/nuvoton/m46x.dtsi:434 */
			clocks = < &pcc 0x48420011 0x2 0x0 >; /* in zephyr/dts/arm/nuvoton/m46x.dtsi:435 */
			#pwm-cells = < 0x3 >;                 /* in zephyr/dts/arm/nuvoton/m46x.dtsi:436 */
			status = "disabled";                  /* in zephyr/dts/arm/nuvoton/m46x.dtsi:437 */
		};

		/* node '/soc/canfd@40020000' defined in zephyr/dts/arm/nuvoton/m46x.dtsi:440 */
		canfd0: canfd@40020000 {
			compatible = "nuvoton,numaker-canfd";                 /* in zephyr/dts/arm/nuvoton/m46x.dtsi:441 */
			reg = < 0x40020000 0x200 >,
			      < 0x40020200 0x1800 >;                          /* in zephyr/dts/arm/nuvoton/m46x.dtsi:442 */
			reg-names = "m_can",
			            "message_ram";                            /* in zephyr/dts/arm/nuvoton/m46x.dtsi:443 */
			interrupts = < 0x70 0x0 >,
			             < 0x71 0x0 >;                            /* in zephyr/dts/arm/nuvoton/m46x.dtsi:444 */
			interrupt-names = "int0",
			                  "int1";                             /* in zephyr/dts/arm/nuvoton/m46x.dtsi:445 */
			resets = < &rst 0x14 >;                               /* in zephyr/dts/arm/nuvoton/m46x.dtsi:446 */
			clocks = < &pcc 0x80f17c14 0x2000000 0x0 >;           /* in zephyr/dts/arm/nuvoton/m46x.dtsi:447 */
			bosch,mram-cfg = < 0x0 0xc 0xa 0x3 0x3 0x3 0x3 0x3 >; /* in zephyr/dts/arm/nuvoton/m46x.dtsi:450 */
			pinctrl-0 = < &canfd0_default >;                      /* in zephyr/boards/nuvoton/numaker_pfm_m467/numaker_pfm_m467.dts:117 */
			pinctrl-names = "default";                            /* in zephyr/boards/nuvoton/numaker_pfm_m467/numaker_pfm_m467.dts:118 */
			status = "okay";                                      /* in zephyr/boards/nuvoton/numaker_pfm_m467/numaker_pfm_m467.dts:119 */
		};

		/* node '/soc/canfd@40024000' defined in zephyr/dts/arm/nuvoton/m46x.dtsi:454 */
		canfd1: canfd@40024000 {
			compatible = "nuvoton,numaker-canfd";                 /* in zephyr/dts/arm/nuvoton/m46x.dtsi:455 */
			reg = < 0x40024000 0x200 >,
			      < 0x40024200 0x1800 >;                          /* in zephyr/dts/arm/nuvoton/m46x.dtsi:456 */
			reg-names = "m_can",
			            "message_ram";                            /* in zephyr/dts/arm/nuvoton/m46x.dtsi:457 */
			interrupts = < 0x72 0x0 >,
			             < 0x73 0x0 >;                            /* in zephyr/dts/arm/nuvoton/m46x.dtsi:458 */
			interrupt-names = "int0",
			                  "int1";                             /* in zephyr/dts/arm/nuvoton/m46x.dtsi:459 */
			resets = < &rst 0x15 >;                               /* in zephyr/dts/arm/nuvoton/m46x.dtsi:460 */
			clocks = < &pcc 0x80f57c95 0x8000000 0x0 >;           /* in zephyr/dts/arm/nuvoton/m46x.dtsi:461 */
			bosch,mram-cfg = < 0x0 0xc 0xa 0x3 0x3 0x3 0x3 0x3 >; /* in zephyr/dts/arm/nuvoton/m46x.dtsi:464 */
			status = "disabled";                                  /* in zephyr/dts/arm/nuvoton/m46x.dtsi:465 */
		};

		/* node '/soc/canfd@40028000' defined in zephyr/dts/arm/nuvoton/m46x.dtsi:468 */
		canfd2: canfd@40028000 {
			compatible = "nuvoton,numaker-canfd";                 /* in zephyr/dts/arm/nuvoton/m46x.dtsi:469 */
			reg = < 0x40028000 0x200 >,
			      < 0x40028200 0x1800 >;                          /* in zephyr/dts/arm/nuvoton/m46x.dtsi:470 */
			reg-names = "m_can",
			            "message_ram";                            /* in zephyr/dts/arm/nuvoton/m46x.dtsi:471 */
			interrupts = < 0x78 0x0 >,
			             < 0x79 0x0 >;                            /* in zephyr/dts/arm/nuvoton/m46x.dtsi:472 */
			interrupt-names = "int0",
			                  "int1";                             /* in zephyr/dts/arm/nuvoton/m46x.dtsi:473 */
			resets = < &rst 0x16 >;                               /* in zephyr/dts/arm/nuvoton/m46x.dtsi:474 */
			clocks = < &pcc 0x80f97d16 0x20000000 0x0 >;          /* in zephyr/dts/arm/nuvoton/m46x.dtsi:475 */
			bosch,mram-cfg = < 0x0 0xc 0xa 0x3 0x3 0x3 0x3 0x3 >; /* in zephyr/dts/arm/nuvoton/m46x.dtsi:478 */
			status = "disabled";                                  /* in zephyr/dts/arm/nuvoton/m46x.dtsi:479 */
		};

		/* node '/soc/canfd@4002c000' defined in zephyr/dts/arm/nuvoton/m46x.dtsi:482 */
		canfd3: canfd@4002c000 {
			compatible = "nuvoton,numaker-canfd";                 /* in zephyr/dts/arm/nuvoton/m46x.dtsi:483 */
			reg = < 0x4002c000 0x200 >,
			      < 0x4002c200 0x1800 >;                          /* in zephyr/dts/arm/nuvoton/m46x.dtsi:484 */
			reg-names = "m_can",
			            "message_ram";                            /* in zephyr/dts/arm/nuvoton/m46x.dtsi:485 */
			interrupts = < 0x7a 0x0 >,
			             < 0x7b 0x0 >;                            /* in zephyr/dts/arm/nuvoton/m46x.dtsi:486 */
			interrupt-names = "int0",
			                  "int1";                             /* in zephyr/dts/arm/nuvoton/m46x.dtsi:487 */
			resets = < &rst 0x17 >;                               /* in zephyr/dts/arm/nuvoton/m46x.dtsi:488 */
			clocks = < &pcc 0x80fd7d97 0x80000000 0x0 >;          /* in zephyr/dts/arm/nuvoton/m46x.dtsi:489 */
			bosch,mram-cfg = < 0x0 0xc 0xa 0x3 0x3 0x3 0x3 0x3 >; /* in zephyr/dts/arm/nuvoton/m46x.dtsi:492 */
			status = "disabled";                                  /* in zephyr/dts/arm/nuvoton/m46x.dtsi:493 */
		};

		/* node '/soc/ethernet@40012000' defined in zephyr/dts/arm/nuvoton/m46x.dtsi:496 */
		emac: ethernet@40012000 {
			compatible = "nuvoton,numaker-ethernet"; /* in zephyr/dts/arm/nuvoton/m46x.dtsi:497 */
			reg = < 0x40012000 0x105c >;             /* in zephyr/dts/arm/nuvoton/m46x.dtsi:498 */
			interrupts = < 0x42 0x0 >;               /* in zephyr/dts/arm/nuvoton/m46x.dtsi:499 */
			resets = < &rst 0x5 >;                   /* in zephyr/dts/arm/nuvoton/m46x.dtsi:500 */
			phy-addr = < 0x1 >;                      /* in zephyr/dts/arm/nuvoton/m46x.dtsi:501 */
			clocks = < &pcc 0xfe05 0x0 0x0 >;        /* in zephyr/dts/arm/nuvoton/m46x.dtsi:502 */
			pinctrl-0 = < &emac_default >;           /* in zephyr/boards/nuvoton/numaker_pfm_m467/numaker_pfm_m467.dts:123 */
			pinctrl-names = "default";               /* in zephyr/boards/nuvoton/numaker_pfm_m467/numaker_pfm_m467.dts:124 */
			status = "okay";                         /* in zephyr/boards/nuvoton/numaker_pfm_m467/numaker_pfm_m467.dts:125 */
		};

		/* node '/soc/i2c@40080000' defined in zephyr/dts/arm/nuvoton/m46x.dtsi:506 */
		i2c0: i2c@40080000 {
			compatible = "nuvoton,numaker-i2c";   /* in zephyr/dts/arm/nuvoton/m46x.dtsi:507 */
			clock-frequency = < 0x186a0 >;        /* in zephyr/dts/arm/nuvoton/m46x.dtsi:508 */
			reg = < 0x40080000 0x1000 >;          /* in zephyr/dts/arm/nuvoton/m46x.dtsi:509 */
			interrupts = < 0x26 0x0 >;            /* in zephyr/dts/arm/nuvoton/m46x.dtsi:510 */
			resets = < &rst 0x4000008 >;          /* in zephyr/dts/arm/nuvoton/m46x.dtsi:511 */
			clocks = < &pcc 0x20000008 0x0 0x0 >; /* in zephyr/dts/arm/nuvoton/m46x.dtsi:512 */
			status = "disabled";                  /* in zephyr/dts/arm/nuvoton/m46x.dtsi:513 */
			#address-cells = < 0x1 >;             /* in zephyr/dts/arm/nuvoton/m46x.dtsi:514 */
			#size-cells = < 0x0 >;                /* in zephyr/dts/arm/nuvoton/m46x.dtsi:515 */
		};

		/* node '/soc/i2c@40081000' defined in zephyr/dts/arm/nuvoton/m46x.dtsi:518 */
		i2c1: i2c@40081000 {
			compatible = "nuvoton,numaker-i2c";   /* in zephyr/dts/arm/nuvoton/m46x.dtsi:519 */
			clock-frequency = < 0x186a0 >;        /* in zephyr/dts/arm/nuvoton/m46x.dtsi:520 */
			reg = < 0x40081000 0x1000 >;          /* in zephyr/dts/arm/nuvoton/m46x.dtsi:521 */
			interrupts = < 0x27 0x0 >;            /* in zephyr/dts/arm/nuvoton/m46x.dtsi:522 */
			resets = < &rst 0x4000009 >;          /* in zephyr/dts/arm/nuvoton/m46x.dtsi:523 */
			clocks = < &pcc 0x20000009 0x0 0x0 >; /* in zephyr/dts/arm/nuvoton/m46x.dtsi:524 */
			status = "disabled";                  /* in zephyr/dts/arm/nuvoton/m46x.dtsi:525 */
			#address-cells = < 0x1 >;             /* in zephyr/dts/arm/nuvoton/m46x.dtsi:526 */
			#size-cells = < 0x0 >;                /* in zephyr/dts/arm/nuvoton/m46x.dtsi:527 */
		};

		/* node '/soc/i2c@40082000' defined in zephyr/dts/arm/nuvoton/m46x.dtsi:530 */
		i2c2: i2c@40082000 {
			compatible = "nuvoton,numaker-i2c";   /* in zephyr/dts/arm/nuvoton/m46x.dtsi:531 */
			clock-frequency = < 0x186a0 >;        /* in zephyr/dts/arm/nuvoton/m46x.dtsi:532 */
			reg = < 0x40082000 0x1000 >;          /* in zephyr/dts/arm/nuvoton/m46x.dtsi:533 */
			interrupts = < 0x52 0x0 >;            /* in zephyr/dts/arm/nuvoton/m46x.dtsi:534 */
			resets = < &rst 0x400000a >;          /* in zephyr/dts/arm/nuvoton/m46x.dtsi:535 */
			clocks = < &pcc 0x2000000a 0x0 0x0 >; /* in zephyr/dts/arm/nuvoton/m46x.dtsi:536 */
			status = "disabled";                  /* in zephyr/dts/arm/nuvoton/m46x.dtsi:537 */
			#address-cells = < 0x1 >;             /* in zephyr/dts/arm/nuvoton/m46x.dtsi:538 */
			#size-cells = < 0x0 >;                /* in zephyr/dts/arm/nuvoton/m46x.dtsi:539 */
		};

		/* node '/soc/i2c@40083000' defined in zephyr/dts/arm/nuvoton/m46x.dtsi:542 */
		i2c3: i2c@40083000 {
			compatible = "nuvoton,numaker-i2c";   /* in zephyr/dts/arm/nuvoton/m46x.dtsi:543 */
			clock-frequency = < 0x186a0 >;        /* in zephyr/dts/arm/nuvoton/m46x.dtsi:544 */
			reg = < 0x40083000 0x1000 >;          /* in zephyr/dts/arm/nuvoton/m46x.dtsi:545 */
			interrupts = < 0x53 0x0 >;            /* in zephyr/dts/arm/nuvoton/m46x.dtsi:546 */
			resets = < &rst 0x400000b >;          /* in zephyr/dts/arm/nuvoton/m46x.dtsi:547 */
			clocks = < &pcc 0x2000000b 0x0 0x0 >; /* in zephyr/dts/arm/nuvoton/m46x.dtsi:548 */
			status = "disabled";                  /* in zephyr/dts/arm/nuvoton/m46x.dtsi:549 */
			#address-cells = < 0x1 >;             /* in zephyr/dts/arm/nuvoton/m46x.dtsi:550 */
			#size-cells = < 0x0 >;                /* in zephyr/dts/arm/nuvoton/m46x.dtsi:551 */
		};

		/* node '/soc/i2c@40084000' defined in zephyr/dts/arm/nuvoton/m46x.dtsi:554 */
		i2c4: i2c@40084000 {
			compatible = "nuvoton,numaker-i2c";   /* in zephyr/dts/arm/nuvoton/m46x.dtsi:555 */
			clock-frequency = < 0x186a0 >;        /* in zephyr/dts/arm/nuvoton/m46x.dtsi:556 */
			reg = < 0x40084000 0x1000 >;          /* in zephyr/dts/arm/nuvoton/m46x.dtsi:557 */
			interrupts = < 0x76 0x0 >;            /* in zephyr/dts/arm/nuvoton/m46x.dtsi:558 */
			resets = < &rst 0x8000003 >;          /* in zephyr/dts/arm/nuvoton/m46x.dtsi:559 */
			clocks = < &pcc 0x40000003 0x0 0x0 >; /* in zephyr/dts/arm/nuvoton/m46x.dtsi:560 */
			status = "disabled";                  /* in zephyr/dts/arm/nuvoton/m46x.dtsi:561 */
			#address-cells = < 0x1 >;             /* in zephyr/dts/arm/nuvoton/m46x.dtsi:562 */
			#size-cells = < 0x0 >;                /* in zephyr/dts/arm/nuvoton/m46x.dtsi:563 */
		};

		/* node '/soc/eadc@40043000' defined in zephyr/dts/arm/nuvoton/m46x.dtsi:566 */
		eadc0: eadc@40043000 {
			compatible = "nuvoton,numaker-adc";         /* in zephyr/dts/arm/nuvoton/m46x.dtsi:567 */
			reg = < 0x40043000 0xffc >;                 /* in zephyr/dts/arm/nuvoton/m46x.dtsi:568 */
			interrupts = < 0x2a 0x0 >;                  /* in zephyr/dts/arm/nuvoton/m46x.dtsi:569 */
			resets = < &rst 0x400001c >;                /* in zephyr/dts/arm/nuvoton/m46x.dtsi:570 */
			clocks = < &pcc 0x20d43e1c 0x800 0xb0000 >; /* in zephyr/dts/arm/nuvoton/m46x.dtsi:571 */
			channels = < 0x13 >;                        /* in zephyr/dts/arm/nuvoton/m46x.dtsi:574 */
			status = "disabled";                        /* in zephyr/dts/arm/nuvoton/m46x.dtsi:575 */
			#io-channel-cells = < 0x1 >;                /* in zephyr/dts/arm/nuvoton/m46x.dtsi:576 */
		};

		/* node '/soc/eadc@4004b000' defined in zephyr/dts/arm/nuvoton/m46x.dtsi:579 */
		eadc1: eadc@4004b000 {
			compatible = "nuvoton,numaker-adc";            /* in zephyr/dts/arm/nuvoton/m46x.dtsi:580 */
			reg = < 0x4004b000 0xffc >;                    /* in zephyr/dts/arm/nuvoton/m46x.dtsi:581 */
			interrupts = < 0x68 0x0 >;                     /* in zephyr/dts/arm/nuvoton/m46x.dtsi:582 */
			resets = < &rst 0x800001f >;                   /* in zephyr/dts/arm/nuvoton/m46x.dtsi:583 */
			clocks = < &pcc 0x40d8001f 0x2000 0xb000000 >; /* in zephyr/dts/arm/nuvoton/m46x.dtsi:584 */
			channels = < 0x13 >;                           /* in zephyr/dts/arm/nuvoton/m46x.dtsi:587 */
			status = "disabled";                           /* in zephyr/dts/arm/nuvoton/m46x.dtsi:588 */
			#io-channel-cells = < 0x1 >;                   /* in zephyr/dts/arm/nuvoton/m46x.dtsi:589 */
		};

		/* node '/soc/eadc@40097000' defined in zephyr/dts/arm/nuvoton/m46x.dtsi:592 */
		eadc2: eadc@40097000 {
			compatible = "nuvoton,numaker-adc";            /* in zephyr/dts/arm/nuvoton/m46x.dtsi:593 */
			reg = < 0x40097000 0xffc >;                    /* in zephyr/dts/arm/nuvoton/m46x.dtsi:594 */
			interrupts = < 0x7c 0x0 >;                     /* in zephyr/dts/arm/nuvoton/m46x.dtsi:595 */
			resets = < &rst 0x18000006 >;                  /* in zephyr/dts/arm/nuvoton/m46x.dtsi:596 */
			clocks = < &pcc 0x60dcbf06 0x8000 0xb000000 >; /* in zephyr/dts/arm/nuvoton/m46x.dtsi:597 */
			channels = < 0x13 >;                           /* in zephyr/dts/arm/nuvoton/m46x.dtsi:600 */
			status = "disabled";                           /* in zephyr/dts/arm/nuvoton/m46x.dtsi:601 */
			#io-channel-cells = < 0x1 >;                   /* in zephyr/dts/arm/nuvoton/m46x.dtsi:602 */
		};

		/* node '/soc/usbd@400c0000' defined in zephyr/dts/arm/nuvoton/m46x.dtsi:605 */
		usbd: zephyr_udc0: usbd@400c0000 {
			compatible = "nuvoton,numaker-usbd";  /* in zephyr/dts/arm/nuvoton/m46x.dtsi:606 */
			reg = < 0x400c0000 0x1000 >;          /* in zephyr/dts/arm/nuvoton/m46x.dtsi:607 */
			interrupts = < 0x35 0x0 >;            /* in zephyr/dts/arm/nuvoton/m46x.dtsi:608 */
			resets = < &rst 0x400001b >;          /* in zephyr/dts/arm/nuvoton/m46x.dtsi:609 */
			clocks = < &pcc 0x20503c9b 0x0 0x0 >; /* in zephyr/dts/arm/nuvoton/m46x.dtsi:610 */
			dma-buffer-size = < 0x600 >;          /* in zephyr/dts/arm/nuvoton/m46x.dtsi:612 */
			num-bidir-endpoints = < 0x19 >;       /* in zephyr/dts/arm/nuvoton/m46x.dtsi:614 */
			disallow-iso-in-out-same-number;      /* in zephyr/dts/arm/nuvoton/m46x.dtsi:615 */
			pinctrl-0 = < &usbd_default >;        /* in zephyr/boards/nuvoton/numaker_pfm_m467/numaker_pfm_m467.dts:130 */
			pinctrl-names = "default";            /* in zephyr/boards/nuvoton/numaker_pfm_m467/numaker_pfm_m467.dts:131 */
			status = "okay";                      /* in zephyr/boards/nuvoton/numaker_pfm_m467/numaker_pfm_m467.dts:132 */
		};

		/* node '/soc/watchdog@40040100' defined in zephyr/dts/arm/nuvoton/m46x.dtsi:618 */
		wwdt: watchdog@40040100 {
			compatible = "nuvoton,numaker-wwdt";         /* in zephyr/dts/arm/nuvoton/m46x.dtsi:619 */
			reg = < 0x40040100 0x10 >;                   /* in zephyr/dts/arm/nuvoton/m46x.dtsi:620 */
			interrupts = < 0x9 0x0 >;                    /* in zephyr/dts/arm/nuvoton/m46x.dtsi:621 */
			clocks = < &pcc 0x24fc0000 0xc0000000 0x0 >; /* in zephyr/dts/arm/nuvoton/m46x.dtsi:622 */
			status = "disabled";                         /* in zephyr/dts/arm/nuvoton/m46x.dtsi:623 */
		};

		/* node '/soc/rtc@40041000' defined in zephyr/dts/arm/nuvoton/m46x.dtsi:626 */
		rtc: rtc@40041000 {
			compatible = "nuvoton,numaker-rtc";   /* in zephyr/dts/arm/nuvoton/m46x.dtsi:627 */
			reg = < 0x40041000 0x138 >;           /* in zephyr/dts/arm/nuvoton/m46x.dtsi:628 */
			interrupts = < 0x6 0x0 >;             /* in zephyr/dts/arm/nuvoton/m46x.dtsi:629 */
			oscillator = "lxt";                   /* in zephyr/dts/arm/nuvoton/m46x.dtsi:630 */
			clocks = < &pcc 0x20000001 0x0 0x0 >; /* in zephyr/dts/arm/nuvoton/m46x.dtsi:631 */
			alarms-count = < 0x1 >;               /* in zephyr/dts/arm/nuvoton/m46x.dtsi:632 */
		};
	};

	/* node '/cpus' defined in zephyr/dts/arm/nuvoton/m46x.dtsi:25 */
	cpus {
		#address-cells = < 0x1 >; /* in zephyr/dts/arm/nuvoton/m46x.dtsi:26 */
		#size-cells = < 0x0 >;    /* in zephyr/dts/arm/nuvoton/m46x.dtsi:27 */

		/* node '/cpus/cpu@0' defined in zephyr/dts/arm/nuvoton/m46x.dtsi:29 */
		cpu@0 {
			device_type = "cpu";           /* in zephyr/dts/arm/nuvoton/m46x.dtsi:30 */
			compatible = "arm,cortex-m4f"; /* in zephyr/dts/arm/nuvoton/m46x.dtsi:31 */
			reg = < 0x0 >;                 /* in zephyr/dts/arm/nuvoton/m46x.dtsi:32 */
		};
	};

	/* node '/memory@20000000' defined in zephyr/dts/arm/nuvoton/m46x.dtsi:36 */
	sram0: memory@20000000 {
		compatible = "mmio-sram";     /* in zephyr/dts/arm/nuvoton/m46x.dtsi:37 */
		reg = < 0x20000000 0x80000 >; /* in zephyr/boards/nuvoton/numaker_pfm_m467/numaker_pfm_m467.dts:106 */
	};

	/* node '/system-clock' defined in zephyr/dts/arm/nuvoton/m46x.dtsi:41 */
	sysclk: system-clock {
		compatible = "fixed-clock";      /* in zephyr/dts/arm/nuvoton/m46x.dtsi:42 */
		clock-frequency = < 0xbebc200 >; /* in zephyr/dts/arm/nuvoton/m46x.dtsi:43 */
		#clock-cells = < 0x0 >;          /* in zephyr/dts/arm/nuvoton/m46x.dtsi:44 */
	};

	/* node '/leds' defined in zephyr/boards/nuvoton/numaker_pfm_m467/numaker_pfm_m467.dts:34 */
	leds {
		compatible = "gpio-leds"; /* in zephyr/boards/nuvoton/numaker_pfm_m467/numaker_pfm_m467.dts:35 */

		/* node '/leds/led_0' defined in zephyr/boards/nuvoton/numaker_pfm_m467/numaker_pfm_m467.dts:37 */
		red_led: led_0 {
			gpios = < &gpioh 0x4 0x1 >; /* in zephyr/boards/nuvoton/numaker_pfm_m467/numaker_pfm_m467.dts:38 */
			label = "User LD1";         /* in zephyr/boards/nuvoton/numaker_pfm_m467/numaker_pfm_m467.dts:39 */
		};

		/* node '/leds/led_1' defined in zephyr/boards/nuvoton/numaker_pfm_m467/numaker_pfm_m467.dts:42 */
		green_led: led_1 {
			gpios = < &gpioh 0x6 0x1 >; /* in zephyr/boards/nuvoton/numaker_pfm_m467/numaker_pfm_m467.dts:43 */
			label = "User LD2";         /* in zephyr/boards/nuvoton/numaker_pfm_m467/numaker_pfm_m467.dts:44 */
		};

		/* node '/leds/led_2' defined in zephyr/boards/nuvoton/numaker_pfm_m467/numaker_pfm_m467.dts:47 */
		blue_led: led_2 {
			gpios = < &gpioh 0x5 0x1 >; /* in zephyr/boards/nuvoton/numaker_pfm_m467/numaker_pfm_m467.dts:48 */
			label = "User LD3";         /* in zephyr/boards/nuvoton/numaker_pfm_m467/numaker_pfm_m467.dts:49 */
		};
	};

	/* node '/gpio_keys' defined in zephyr/boards/nuvoton/numaker_pfm_m467/numaker_pfm_m467.dts:53 */
	gpio_keys {
		compatible = "gpio-keys"; /* in zephyr/boards/nuvoton/numaker_pfm_m467/numaker_pfm_m467.dts:54 */

		/* node '/gpio_keys/button_1' defined in zephyr/boards/nuvoton/numaker_pfm_m467/numaker_pfm_m467.dts:56 */
		user_button_1: button_1 {
			label = "User SW2";         /* in zephyr/boards/nuvoton/numaker_pfm_m467/numaker_pfm_m467.dts:57 */
			gpios = < &gpioh 0x1 0x1 >; /* in zephyr/boards/nuvoton/numaker_pfm_m467/numaker_pfm_m467.dts:58 */
			zephyr,code = < 0xb >;      /* in zephyr/boards/nuvoton/numaker_pfm_m467/numaker_pfm_m467.dts:59 */
		};

		/* node '/gpio_keys/button_2' defined in zephyr/boards/nuvoton/numaker_pfm_m467/numaker_pfm_m467.dts:62 */
		user_button_2: button_2 {
			label = "User SW3";         /* in zephyr/boards/nuvoton/numaker_pfm_m467/numaker_pfm_m467.dts:63 */
			gpios = < &gpioh 0x0 0x1 >; /* in zephyr/boards/nuvoton/numaker_pfm_m467/numaker_pfm_m467.dts:64 */
			zephyr,code = < 0x2 >;      /* in zephyr/boards/nuvoton/numaker_pfm_m467/numaker_pfm_m467.dts:65 */
		};
	};
};
